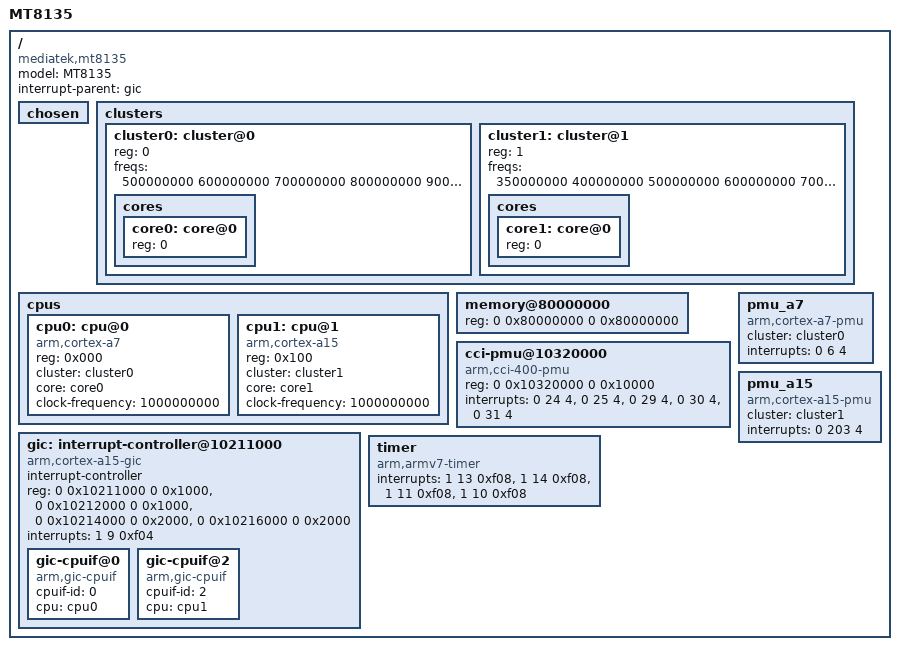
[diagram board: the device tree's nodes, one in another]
/*
 * MediaTek MT8135
 *
 * Cortex-A7x1 Cortex-A15x1
 */

/dts-v1/;

/memreserve/ 0xff000000 0x01000000;

/ {
	model = "MT8135";
	compatible = "mediatek,mt8135";
	interrupt-parent = <&gic>;
	#address-cells = <2>;
	#size-cells = <2>;

	chosen { };

	clusters {
		#address-cells = <1>;
		#size-cells = <0>;

		cluster0: cluster@0 {
			reg = <0>;
			freqs = <500000000 600000000 700000000 800000000 900000000 1000000000 1100000000 1200000000>;
			cores {
				#address-cells = <1>;
				#size-cells = <0>;

				core0: core@0 {
					reg = <0>;
				};
			};
		};

		cluster1: cluster@1 {
			reg = <1>;
			freqs = <350000000 400000000 500000000 600000000 700000000 800000000 900000000 1000000000>;
			cores {
				#address-cells = <1>;
				#size-cells = <0>;

				core1: core@0 {
					reg = <0>;
				};
			};
		};
	};

	cpus {
		#address-cells = <1>;
		#size-cells = <0>;

		cpu0: cpu@0 {
			device_type = "cpu";
			compatible = "arm,cortex-a7";
			reg = <0x000>;
			cluster = <&cluster0>;
			core = <&core0>;
			clock-frequency = <1000000000>;
		};


		cpu1: cpu@1 {
			device_type = "cpu";
			compatible = "arm,cortex-a15";
			reg = <0x100>;
			cluster = <&cluster1>;
			core = <&core1>;
			clock-frequency = <1000000000>;
		};

	};

	memory@80000000 {
		device_type = "memory";
		reg = <0 0x80000000 0 0x80000000>;
	};

	cci-pmu@10320000 {
		compatible = "arm,cci-400-pmu";
		reg = <0 0x10320000 0 0x10000>;
		interrupts = <0 24 4>,
			     <0 25 4>,
			     <0 29 4>,
			     <0 30 4>,
			     <0 31 4>;
	};

	gic: interrupt-controller@10211000 {
		compatible = "arm,cortex-a15-gic", "arm,cortex-a9-gic";
		#interrupt-cells = <3>;
		#address-cells = <0>;
		interrupt-controller;
		reg = <0 0x10211000 0 0x1000>,
		      <0 0x10212000 0 0x1000>,
		      <0 0x10214000 0 0x2000>,
		      <0 0x10216000 0 0x2000>;
		interrupts = <1 9 0xf04>;

		gic-cpuif@0 {
			compatible = "arm,gic-cpuif";
			cpuif-id = <0>;
			cpu = <&cpu0>;
		};
		gic-cpuif@2 {
			compatible = "arm,gic-cpuif";
			cpuif-id = <2>;
			cpu = <&cpu1>;
		};
	};

	timer {
		compatible = "arm,armv7-timer";
		interrupts = <1 13 0xf08>,
			     <1 14 0xf08>,
			     <1 11 0xf08>,
			     <1 10 0xf08>;
	};

	pmu_a7 {
		compatible = "arm,cortex-a7-pmu";
		cluster  = <&cluster0>;
		interrupts = <0 6 4>;
	};

	pmu_a15 {
		compatible = "arm,cortex-a15-pmu";
		cluster  = <&cluster1>;
		interrupts = <0 203 4>;
	};
};
